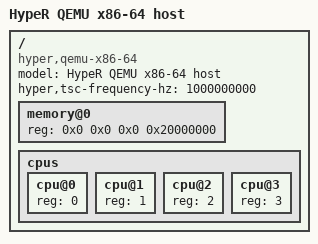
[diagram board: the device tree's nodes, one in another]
/*
 * SPDX-FileCopyrightText: 2026 roolrz
 * SPDX-License-Identifier: Apache-2.0
 */

/dts-v1/;

/memreserve/ 0x00000000 0x00100000;

/ {
    compatible = "hyper,qemu-x86-64";
    model = "HypeR QEMU x86-64 host";
    #address-cells = <2>;
    #size-cells = <2>;
    hyper,tsc-frequency-hz = /bits/ 64 <1000000000>;

    memory@0 {
        device_type = "memory";
        reg = <0x0 0x0 0x0 0x20000000>;
    };

    cpus {
        #address-cells = <1>;
        #size-cells = <0>;

        cpu@0 { device_type = "cpu"; reg = <0>; };
        cpu@1 { device_type = "cpu"; reg = <1>; };
        cpu@2 { device_type = "cpu"; reg = <2>; };
        cpu@3 { device_type = "cpu"; reg = <3>; };
    };
};
